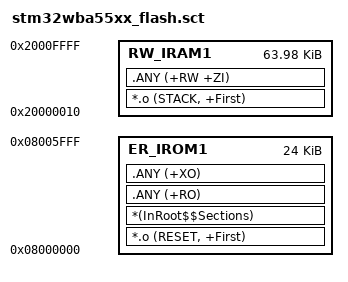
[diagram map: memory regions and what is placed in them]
; *************************************************************
; *** Scatter-Loading Description File                      ***
; *************************************************************
LR_IROM1 0x08000000 0x6000 {       ; load region size_region
  ER_IROM1 0x08000000 0x6000 { ; load address = execution address
    *.o (RESET, +First)
    *(InRoot$$Sections)
    .ANY (+RO)
    .ANY (+XO)
  }

  RW_IRAM1 0x20000010 0xFFF0 {
    *.o (STACK, +First)
    .ANY (+RW +ZI)
  }
}

